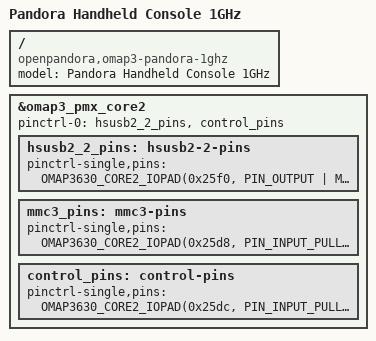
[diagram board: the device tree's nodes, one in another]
/dts-v1/;
#include "omap36xx.dtsi"
#include "omap3-pandora-common.dtsi"
/ {
	model = "Pandora Handheld Console 1GHz";
	compatible = "openpandora,omap3-pandora-1ghz", "ti,omap3630", "ti,omap3";
};
&omap3_pmx_core2 {
	pinctrl-names = "default";
	pinctrl-0 = <
		&hsusb2_2_pins
		&control_pins
	>;
	hsusb2_2_pins: hsusb2-2-pins {
		pinctrl-single,pins = <
			OMAP3630_CORE2_IOPAD(0x25f0, PIN_OUTPUT | MUX_MODE3)		 
			OMAP3630_CORE2_IOPAD(0x25f2, PIN_OUTPUT | MUX_MODE3)		 
			OMAP3630_CORE2_IOPAD(0x25f4, PIN_INPUT_PULLDOWN | MUX_MODE3)	 
			OMAP3630_CORE2_IOPAD(0x25f6, PIN_INPUT_PULLDOWN | MUX_MODE3)	 
			OMAP3630_CORE2_IOPAD(0x25f8, PIN_INPUT_PULLDOWN | MUX_MODE3)	 
			OMAP3630_CORE2_IOPAD(0x25fa, PIN_INPUT_PULLDOWN | MUX_MODE3)	 
		>;
	};
	mmc3_pins: mmc3-pins {
		pinctrl-single,pins = <
			OMAP3630_CORE2_IOPAD(0x25d8, PIN_INPUT_PULLUP | MUX_MODE2)	 
			OMAP3630_CORE2_IOPAD(0x25da, PIN_INPUT_PULLUP | MUX_MODE2)	 
			OMAP3630_CORE2_IOPAD(0x25e2, PIN_INPUT_PULLUP | MUX_MODE2)	 
			OMAP3630_CORE2_IOPAD(0x25e4, PIN_INPUT_PULLUP | MUX_MODE2)	 
			OMAP3630_CORE2_IOPAD(0x25e6, PIN_INPUT_PULLUP | MUX_MODE2)	 
			OMAP3630_CORE2_IOPAD(0x25e8, PIN_INPUT_PULLUP | MUX_MODE2)	 
		>;
	};
	control_pins: control-pins {
		pinctrl-single,pins = <
			OMAP3630_CORE2_IOPAD(0x25dc, PIN_INPUT_PULLDOWN | MUX_MODE4)	 
			OMAP3630_CORE2_IOPAD(0x25de, PIN_OUTPUT | MUX_MODE4)		 
			OMAP3630_CORE2_IOPAD(0x25e0, PIN_OUTPUT | MUX_MODE4)		 
			OMAP3630_CORE2_IOPAD(0x25ea, PIN_INPUT | MUX_MODE4)		 
			OMAP3630_CORE2_IOPAD(0x25ec, PIN_OUTPUT | MUX_MODE4)		 
			OMAP3630_CORE2_IOPAD(0x25ee, PIN_OUTPUT | MUX_MODE4)		 
			OMAP3_WKUP_IOPAD(0x2a54, PIN_INPUT | MUX_MODE4)   		 
			OMAP3_WKUP_IOPAD(0x2a56, PIN_INPUT | MUX_MODE4)   		 
			OMAP3_WKUP_IOPAD(0x2a58, PIN_OUTPUT | MUX_MODE4)   		 
			OMAP3_WKUP_IOPAD(0x2a5a, PIN_OUTPUT | MUX_MODE4)   		 
		>;
	};
};
